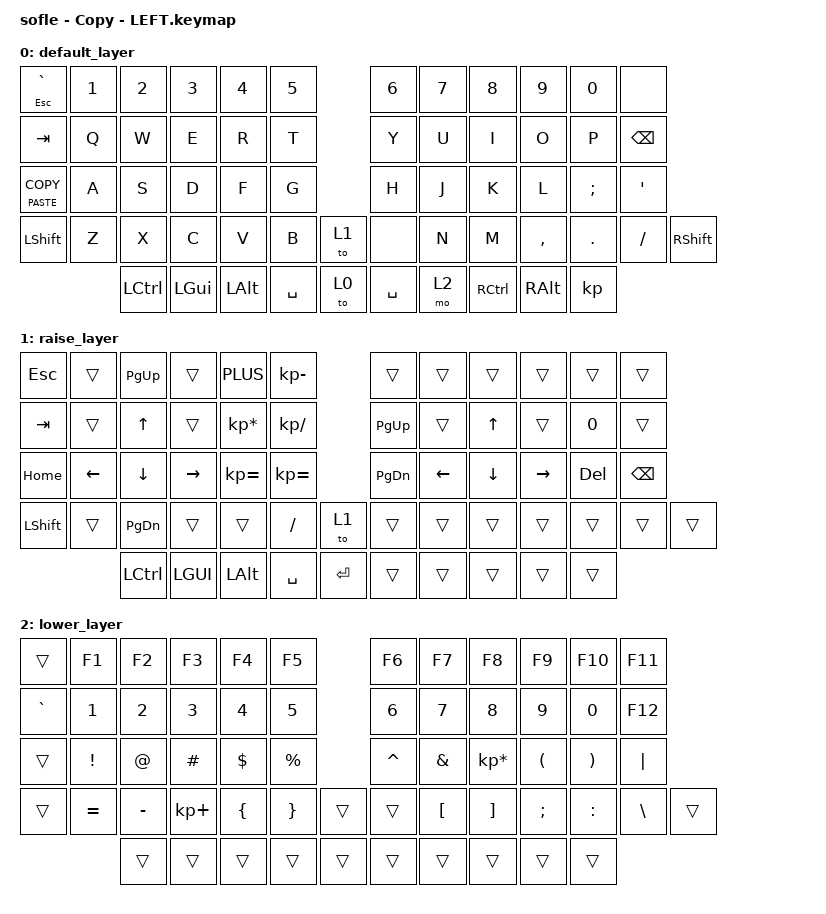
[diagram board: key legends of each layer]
/*
 * Copyright (c) 2020 The ZMK Contributors
 *
 * SPDX-License-Identifier: MIT
 * FINAL CONFIG: sensor-bindings = <&inc_dec_kp C_VOL_UP C_VOL_DN>;
 */

#include <behaviors.dtsi>
#include <dt-bindings/zmk/keys.h>
#include <dt-bindings/zmk/bt.h>

#define NUMBER 0
#define PRINT 1
#define FUNCTION 2


/ {
    keymap {
        compatible = "zmk,keymap";

        default_layer {
// ------------------------------------------------------------------------------------------------------------
// |  ESC `|  1  |  2  |  3   |  4   |  5   |                   |  6   |  7    |  8    |  9   |   0   |       |
// |  TAB  |  Q  |  W  |  E   |  R   |  T   |                   |  Y   |  U    |  I    |  O   |   P   | BKSPC |
// |  C&P  |  A  |  S  |  D   |  F   |  G   |                   |  H   |  J    |  K    |  L   |   ;   |   '   |
// | SHIFT |  Z  |  X  |  C   |  V   |  B   |  NUMBERS  |  |       |  N   |  M    |  ,    |  .   |   /   | SHIFT |
//               |CTRL | GUI  | ALT	 | SPACE|  ENTER |  | SPACE | RAISE| CTRL  | ALT   | GUI  |
            bindings = <
&mt ESC GRAVE 		  &kp N1 &kp N2   &kp N3   &kp N4    &kp N5                      &kp N6 &kp N7    &kp N8    &kp N9   &kp N0   &none
&kp TAB   			  &kp Q  &kp W    &kp E    &kp R     &kp T                       &kp Y  &kp U     &kp I     &kp O    &kp P    &kp BSPC
&mt K_PASTE K_COPY    &kp A  &kp S    &kp D    &kp F     &kp G                       &kp H  &kp J     &kp K     &kp L    &kp SEMI &kp SQT
&kp LSHFT 			  &kp Z  &kp X    &kp C    &kp V     &kp B  &to 1 &none     &kp N  &kp M     &kp COMMA &kp DOT  &kp FSLH &kp RSHFT
							 &kp LCTRL &kp LGUI &kp LALT  &kp SPACE &to 0 &kp SPACE &mo 2  &kp RCTRL &kp RALT  &kp  	
            >;

			sensor-bindings = <&inc_dec_kp C_VOL_DN C_VOL_UP>;
        };
		
        raise_layer {
// -----------------------------------------------------						-------------------------------------------------------
// | ESC | NONE  | PG UP| NONE  |  + 	| -	   |         						       |      |      |       |      |       |       |
// | TAB | NONE  | UP   | NONE  |  *    | /    |         						       | PGUP |      |   ^   |      |       |       |
// | HOME| LEFT  | DOWN | RIGHT | END   | =    |         						       | PGDN |   <- |   v   |  ->  |  DEL  | BKSPC |
// |SHIFT| NONE  | PG DN| NONE  | NONE  | / ?  |      | 						|      |      |      |       |      |       |       |
//               | CTRL |  GUI  | ALT   |SPACE |      | 						|      |      |      |       |      |
            bindings = <
&kp ESC 	  &trans    &kp PAGE_UP   &trans 	&kp K_PLUS 		&kp KP_MINUS    			&trans    &trans    &trans   &trans    &trans  &trans
&kp TAB       &trans    &kp UP        &trans  	&kp KP_MULTIPLY &kp KP_DIVIDE   			&kp PG_UP &trans    &kp UP   &trans    &kp N0  &trans
&kp HOME      &kp LEFT  &kp DOWN      &kp RIGHT &kp KP_EQUAL    &kp KP_EQUAL    			&kp PG_DN &kp LEFT  &kp DOWN &kp RIGHT &kp DEL &kp BSPC
&kp LSHIFT    &trans    &kp PAGE_DOWN &trans   	&trans  		&kp SLASH   	&to 1   	&trans  &trans    &trans    &trans   &trans    &trans  &trans
					    &kp LCTRL      &LGUI    &kp LALT        &kp SPACE	    &kp RET		&trans  &trans    &trans    &trans   &trans
            >;

            sensor-bindings = <&inc_dec_kp C_VOL_UP C_VOL_DN &inc_dec_kp PG_UP PG_DN>;
        };
        lower_layer {
// TODO: Some binds are waiting for shifted keycode support.
// ------------------------------------------------------------------------------------------------------------
// |       |  F1 |  F2 |  F3  |  F4  |  F5  |                   |  F6  |  F7   |  F8   |  F9  |  F10  |  F11  |
// | `     |   1 |   2 |   3  |   4  |   5  |                   |   6  |   7   |   8   |   9  |    0  |  F12  |
// |       |  !  |  @  |  #   |  $   |  %   |                   |  ^   |  &    |  *    |  (   |   )   |   |   |
// |       |  =  |  -  |  +   |  {   |  }   |        |  |       |  [   |  ]    |  ;    |  :   |   \   |       |
//               |     |      |      |      |        |  |       |      |       |       |      |
            bindings = <
&trans    &kp F1    &kp F2    &kp F3      &kp F4    &kp F5                    &kp F6    &kp F7   &kp F8          &kp F9    &kp F10   &kp F11
&kp GRAVE &kp N1    &kp N2    &kp N3      &kp N4    &kp N5                    &kp N6    &kp N7   &kp N8          &kp N9    &kp N0    &kp F12
&trans    &kp EXCL  &kp AT    &kp HASH    &kp DLLR  &kp PRCNT                 &kp CARET &kp AMPS &kp KP_MULTIPLY &kp LPAR  &kp RPAR  &kp PIPE
&trans    &kp EQUAL &kp MINUS &kp KP_PLUS &kp LBRC  &kp RBRC  &trans   &trans &kp LBKT  &kp RBKT &kp SEMI        &kp COLON &kp BSLH  &trans
                    &trans    &trans      &trans    &trans    &trans   &trans &trans    &trans   &trans          &trans
            >;

            sensor-bindings = <&inc_dec_kp C_VOL_UP C_VOL_DN &inc_dec_kp PG_UP PG_DN>;
        };


    };
};
